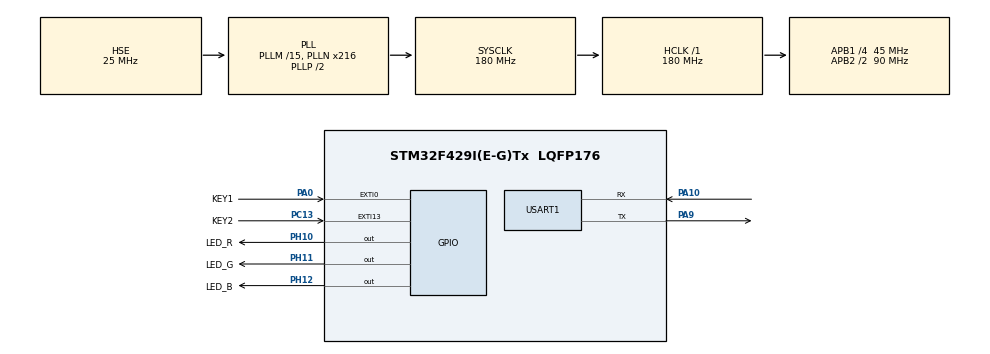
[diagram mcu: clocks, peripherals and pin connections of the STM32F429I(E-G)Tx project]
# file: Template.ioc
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Mcu.Family=STM32F4
RCC.PLLSourceVirtual=RCC_PLLSOURCE_HSE
Dma.USART1_RX.1.Instance=DMA2_Stream2
RCC.CortexFreq_Value=180000000
Dma.USART1_RX.1.MemDataAlignment=DMA_MDATAALIGN_BYTE
Dma.USART1_TX.0.MemInc=DMA_MINC_ENABLE
PH12.Signal=GPIO_Output
Dma.USART1_TX.0.PeriphInc=DMA_PINC_DISABLE
PA10.Mode=Asynchronous
PH10.Signal=GPIO_Output
PH11.Signal=GPIO_Output
PH12.GPIO_Label=LED_B
PH12.GPIO_Speed=GPIO_SPEED_FREQ_HIGH
PH10.PinState=GPIO_PIN_SET
PC13.Signal=GPXTI13
PA0/WKUP.Signal=GPXTI0
PC13.GPIO_Label=KEY2
RCC.APB1CLKDivider=RCC_HCLK_DIV4
RCC.SYSCLKSource=RCC_SYSCLKSOURCE_PLLCLK
ProjectManager.StackSize=0x400
PA13.Signal=SYS_JTMS-SWDIO
PH11.GPIO_Speed=GPIO_SPEED_FREQ_HIGH
PA9.Mode=Asynchronous
Dma.USART1_TX.0.Priority=DMA_PRIORITY_MEDIUM
Dma.USART1_TX.0.Direction=DMA_MEMORY_TO_PERIPH
ProjectManager.TargetToolchain=MDK-ARM V5
PH0/OSC_IN.Mode=HSE-External-Oscillator
RCC.HCLKFreq_Value=180000000
PH11.PinState=GPIO_PIN_SET
RCC.APB2TimFreq_Value=180000000
PA9.Signal=USART1_TX
PH11.GPIO_Label=LED_G
PH1/OSC_OUT.Signal=RCC_OSC_OUT
Dma.USART1_RX.1.MemInc=DMA_MINC_ENABLE
RCC.LSE_VALUE=32768
RCC.AHBFreq_Value=180000000
PH10.GPIO_Label=LED_R
NVIC.EXTI15_10_IRQn=true\:2\:0\:true\:false\:true\:true\:true
RCC.HSE_VALUE=25000000
Dma.USART1_RX.1.PeriphDataAlignment=DMA_PDATAALIGN_BYTE
Dma.USART1_RX.1.FIFOMode=DMA_FIFOMODE_DISABLE
Dma.USART1_TX.0.Mode=DMA_NORMAL
board=custom
RCC.VCOOutputFreq_Value=360000000
PH0/OSC_IN.Signal=RCC_OSC_IN
RCC.APB2Freq_Value=90000000
PA14.Mode=Serial_Wire
PA0/WKUP.GPIO_Label=KEY1
PA0/WKUP.GPIO_ModeDefaultEXTI=GPIO_MODE_IT_FALLING
PA13.Mode=Serial_Wire
Dma.USART1_TX.0.PeriphDataAlignment=DMA_PDATAALIGN_BYTE
PH1/OSC_OUT.Mode=HSE-External-Oscillator
Mcu.Name=STM32F429I(E-G)Tx
Dma.USART1_RX.1.Mode=DMA_NORMAL
RCC.48MHZClocksFreq_Value=90000000
NVIC.EXTI0_IRQn=true\:1\:0\:true\:false\:true\:true\:true
RCC.SYSCLKFreq_VALUE=180000000
Mcu.Package=LQFP176
PH10.GPIO_Speed=GPIO_SPEED_FREQ_HIGH
NVIC.DMA2_Stream7_IRQn=true\:0\:0\:false\:false\:true\:false\:true
PC13.GPIO_ModeDefaultEXTI=GPIO_MODE_IT_FALLING
USART1.VirtualMode=VM_ASYNC
Dma.USART1_TX.0.MemDataAlignment=DMA_MDATAALIGN_BYTE
PH12.PinState=GPIO_PIN_SET
PA10.Signal=USART1_RX
PA14.Signal=SYS_JTCK-SWCLK
ProjectManager.HeapSize=0x200
Dma.USART1_TX.0.Instance=DMA2_Stream7
Dma.USART1_TX.0.FIFOMode=DMA_FIFOMODE_DISABLE
RCC.HSI_VALUE=16000000
Dma.USART1_RX.1.PeriphInc=DMA_PINC_DISABLE
NVIC.PriorityGroup=NVIC_PRIORITYGROUP_4
RCC.APB2CLKDivider=RCC_HCLK_DIV2
NVIC.DMA2_Stream2_IRQn=true\:0\:0\:false\:false\:true\:false\:true
RCC.PLLM=15
RCC.PLLN=216
Dma.Request1=USART1_RX
RCC.APB1TimFreq_Value=90000000
Dma.USART1_RX.1.Direction=DMA_PERIPH_TO_MEMORY
Dma.USART1_RX.1.Priority=DMA_PRIORITY_MEDIUM
Dma.Request0=USART1_TX
RCC.APB1Freq_Value=45000000

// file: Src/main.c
/* USER CODE BEGIN Header */
/**
  ******************************************************************************
  * @file           : main.c
  * @brief          : Main program body
  ******************************************************************************
  * @attention
  *
  * <h2><center>&copy; Copyright (c) 2020 STMicroelectronics.
  * All rights reserved.</center></h2>
  *
  * This software component is licensed by ST under BSD 3-Clause license,
  * the "License"; You may not use this file except in compliance with the
  * License. You may obtain a copy of the License at:
  *                        opensource.org/licenses/BSD-3-Clause
  *
  ******************************************************************************
  */
/* USER CODE END Header */

#include "main.h"
#include "dma.h"
#include "usart.h"
#include "gpio.h"
#include <string.h>
#include "CommonService.h"
#include "Serial.h"

void SystemClock_Config(void);

int main(void)
{
  /* USER CODE BEGIN 1 */
  // char ch;
  char str[] = "Testing USART1 DMA Transmit.\n";
  /* USER CODE END 1 */

  /* MCU Configuration--------------------------------------------------------*/

  /* Reset of all peripherals, Initializes the Flash interface and the Systick. */
  HAL_Init();

  /* Configure the system clock */
  SystemClock_Config();

  /* Initialize all configured peripherals */
  MX_GPIO_Init();
  MX_DMA_Init();
  MX_USART1_UART_Init();
  /* USER CODE BEGIN 2 */
  SetUartTxData(&Uart1_Msg, (uint8_t *)str, strlen(str));

  /* USER CODE END 2 */
  /* Infinite loop */
  while (1)
  {
    // Delay(0xffffff);
    UartRxProcessing(&Uart1_Msg);
    UartTxProcessing(&Uart1_Msg);
    // HAL_UART_IRQHandler
  }
}

void SystemClock_Config(void)
{
  RCC_OscInitTypeDef RCC_OscInitStruct = {0};
  RCC_ClkInitTypeDef RCC_ClkInitStruct = {0};

  /** Configure the main internal regulator output voltage
  */
  __HAL_RCC_PWR_CLK_ENABLE();
  __HAL_PWR_VOLTAGESCALING_CONFIG(PWR_REGULATOR_VOLTAGE_SCALE1);
  /** Initializes the CPU, AHB and APB busses clocks
  */
  RCC_OscInitStruct.OscillatorType = RCC_OSCILLATORTYPE_HSE;
  RCC_OscInitStruct.HSEState = RCC_HSE_ON;
  RCC_OscInitStruct.PLL.PLLState = RCC_PLL_ON;
  RCC_OscInitStruct.PLL.PLLSource = RCC_PLLSOURCE_HSE;
  RCC_OscInitStruct.PLL.PLLM = 15;
  RCC_OscInitStruct.PLL.PLLN = 216;
  RCC_OscInitStruct.PLL.PLLP = RCC_PLLP_DIV2;
  RCC_OscInitStruct.PLL.PLLQ = 4;
  if (HAL_RCC_OscConfig(&RCC_OscInitStruct) != HAL_OK)
  {
    Error_Handler();
  }
  /** Activate the Over-Drive mode
  */
  if (HAL_PWREx_EnableOverDrive() != HAL_OK)
  {
    Error_Handler();
  }
  /** Initializes the CPU, AHB and APB busses clocks
  */
  RCC_ClkInitStruct.ClockType = RCC_CLOCKTYPE_HCLK | RCC_CLOCKTYPE_SYSCLK | RCC_CLOCKTYPE_PCLK1 | RCC_CLOCKTYPE_PCLK2;
  RCC_ClkInitStruct.SYSCLKSource = RCC_SYSCLKSOURCE_PLLCLK;
  RCC_ClkInitStruct.AHBCLKDivider = RCC_SYSCLK_DIV1;
  RCC_ClkInitStruct.APB1CLKDivider = RCC_HCLK_DIV4;
  RCC_ClkInitStruct.APB2CLKDivider = RCC_HCLK_DIV2;

  if (HAL_RCC_ClockConfig(&RCC_ClkInitStruct, FLASH_LATENCY_5) != HAL_OK)
  {
    Error_Handler();
  }
}

void Error_Handler(void)
{
}

/************************ (C) COPYRIGHT STMicroelectronics *****END OF FILE****/
